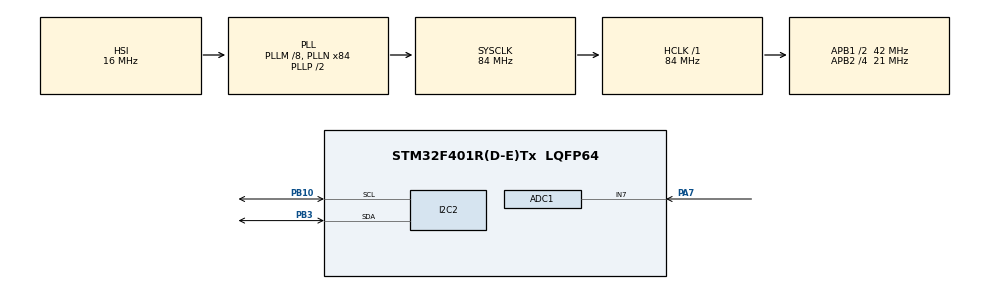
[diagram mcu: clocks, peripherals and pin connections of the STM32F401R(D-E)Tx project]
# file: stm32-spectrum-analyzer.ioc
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Mcu.Family=STM32F4
Dma.ADC1.0.Instance=DMA2_Stream0
RCC.CortexFreq_Value=84000000
PB10.Mode=I2C
ADC1.ContinuousConvMode=ENABLE
PH1\ -\ OSC_OUT.Mode=HSE-External-Oscillator
RCC.APB1CLKDivider=RCC_HCLK_DIV2
RCC.SYSCLKSource=RCC_SYSCLKSOURCE_PLLCLK
ProjectManager.StackSize=0x400
Dma.ADC1.0.PeriphDataAlignment=DMA_PDATAALIGN_HALFWORD
PH0\ -\ OSC_IN.Mode=HSE-External-Oscillator
PH0\ -\ OSC_IN.Signal=RCC_OSC_IN
ProjectManager.TargetToolchain=STM32CubeIDE
Dma.ADC1.0.Mode=DMA_CIRCULAR
SH.ADCx_IN7.0=ADC1_IN7,IN7
RCC.HCLKFreq_Value=84000000
Dma.ADC1.0.Priority=DMA_PRIORITY_LOW
RCC.APB2TimFreq_Value=42000000
ADC1.Channel-1\#ChannelRegularConversion=ADC_CHANNEL_7
Dma.ADC1.0.Direction=DMA_PERIPH_TO_MEMORY
NVIC.DMA2_Stream0_IRQn=true\:0\:0\:false\:false\:true\:false\:true
RCC.LSE_VALUE=32768
Dma.ADC1.0.MemDataAlignment=DMA_MDATAALIGN_HALFWORD
RCC.AHBFreq_Value=84000000
PB10.Signal=I2C2_SCL
RCC.HSE_VALUE=25000000
PH1\ -\ OSC_OUT.Signal=RCC_OSC_OUT
PB3.Mode=I2C
board=custom
RCC.VCOOutputFreq_Value=168000000
RCC.APB2Freq_Value=21000000
Dma.ADC1.0.PeriphInc=DMA_PINC_DISABLE
ADC1.DMAContinuousRequests=ENABLE
Mcu.Name=STM32F401R(D-E)Tx
RCC.48MHZClocksFreq_Value=42000000
PB3.Signal=I2C2_SDA
ADC1.SamplingTime-1\#ChannelRegularConversion=ADC_SAMPLETIME_3CYCLES
RCC.SYSCLKFreq_VALUE=84000000
Mcu.Package=LQFP64
ADC1.master=1
ADC1.Rank-1\#ChannelRegularConversion=1
Dma.ADC1.0.MemInc=DMA_MINC_ENABLE
ProjectManager.HeapSize=0x200
RCC.HSI_VALUE=16000000
NVIC.PriorityGroup=NVIC_PRIORITYGROUP_4
ADC1.NbrOfConversionFlag=1
RCC.APB2CLKDivider=RCC_HCLK_DIV4
RCC.PLLM=8
RCC.PLLN=84
RCC.APB1TimFreq_Value=84000000
Dma.ADC1.0.FIFOMode=DMA_FIFOMODE_DISABLE
RCC.APB1Freq_Value=42000000
Dma.Request0=ADC1
I2C2.I2C_Mode=I2C_Fast
PA7.Signal=ADCx_IN7

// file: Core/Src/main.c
/* USER CODE BEGIN Header */
/**
  ******************************************************************************
  * @file           : main.c
  * @brief          : Main program body
  ******************************************************************************
  * @attention
  *
  * <h2><center>&copy; Copyright (c) 2021 STMicroelectronics.
  * All rights reserved.</center></h2>
  *
  * This software component is licensed by ST under BSD 3-Clause license,
  * the "License"; You may not use this file except in compliance with the
  * License. You may obtain a copy of the License at:
  *                        opensource.org/licenses/BSD-3-Clause
  *
  ******************************************************************************
  */
/* USER CODE END Header */
#include "main.h"

/* USER CODE BEGIN Includes */
#include "arm_math.h"
#include "fonts.h"
#include "ssd1306.h"
/* USER CODE END Includes */

/* USER CODE BEGIN PD */
// #define ARM_MATH_CM4
#define ADC_BUF_LEN 4096
#define FFT_SIZE 256
/* USER CODE END PD */

ADC_HandleTypeDef hadc1;
DMA_HandleTypeDef hdma_adc1;

I2C_HandleTypeDef hi2c2;

/* USER CODE BEGIN PV */
uint16_t adc_buf[ADC_BUF_LEN];

//FFT buffers
float fft_in_buf[FFT_SIZE];
float fft_out_buf[FFT_SIZE];
float32_t fft_mag_buf[FFT_SIZE>>1];

arm_rfft_fast_instance_f32 fft_handler;

float real_fsample = 46785;
uint8_t callback_state = 0;

/* USER CODE END PV */

void SystemClock_Config(void);
static void MX_GPIO_Init(void);
static void MX_DMA_Init(void);
static void MX_ADC1_Init(void);
static void MX_I2C2_Init(void);
/* USER CODE BEGIN PFP */
void displayFFT(uint8_t *arr);
void FFT(void);
/* USER CODE END PFP */

int main(void)
{

  /* MCU Configuration--------------------------------------------------------*/

  /* Reset of all peripherals, Initializes the Flash interface and the Systick. */
  HAL_Init();

  /* Configure the system clock */
  SystemClock_Config();

  /* Initialize all configured peripherals */
  MX_GPIO_Init();
  MX_DMA_Init();
  MX_ADC1_Init();
  MX_I2C2_Init();
  /* USER CODE BEGIN 2 */
  if (ssd1306_Init(&hi2c2) != 0) {
    Error_Handler();
  }
  HAL_Delay(1000);

  ssd1306_Fill(Black);
  ssd1306_UpdateScreen(&hi2c2);

  HAL_ADC_Start_DMA(&hadc1, (uint32_t*)fft_in_buf, ADC_BUF_LEN);

  /* USER CODE END 2 */

  /* Infinite loop */
  /* USER CODE BEGIN WHILE */

  arm_rfft_fast_init_f32(&fft_handler, 256);

  while (1)
  {

    /* USER CODE END WHILE */

    /* USER CODE BEGIN 3 */
	  FFT();

  }
  /* USER CODE END 3 */
}

void SystemClock_Config(void)
{
  RCC_OscInitTypeDef RCC_OscInitStruct = {0};
  RCC_ClkInitTypeDef RCC_ClkInitStruct = {0};

  /** Configure the main internal regulator output voltage
  */
  __HAL_RCC_PWR_CLK_ENABLE();
  __HAL_PWR_VOLTAGESCALING_CONFIG(PWR_REGULATOR_VOLTAGE_SCALE2);
  /** Initializes the RCC Oscillators according to the specified parameters
  * in the RCC_OscInitTypeDef structure.
  */
  RCC_OscInitStruct.OscillatorType = RCC_OSCILLATORTYPE_HSI;
  RCC_OscInitStruct.HSIState = RCC_HSI_ON;
  RCC_OscInitStruct.HSICalibrationValue = RCC_HSICALIBRATION_DEFAULT;
  RCC_OscInitStruct.PLL.PLLState = RCC_PLL_ON;
  RCC_OscInitStruct.PLL.PLLSource = RCC_PLLSOURCE_HSI;
  RCC_OscInitStruct.PLL.PLLM = 8;
  RCC_OscInitStruct.PLL.PLLN = 84;
  RCC_OscInitStruct.PLL.PLLP = RCC_PLLP_DIV2;
  RCC_OscInitStruct.PLL.PLLQ = 4;
  if (HAL_RCC_OscConfig(&RCC_OscInitStruct) != HAL_OK)
  {
    Error_Handler();
  }
  /** Initializes the CPU, AHB and APB buses clocks
  */
  RCC_ClkInitStruct.ClockType = RCC_CLOCKTYPE_HCLK|RCC_CLOCKTYPE_SYSCLK
                              |RCC_CLOCKTYPE_PCLK1|RCC_CLOCKTYPE_PCLK2;
  RCC_ClkInitStruct.SYSCLKSource = RCC_SYSCLKSOURCE_PLLCLK;
  RCC_ClkInitStruct.AHBCLKDivider = RCC_SYSCLK_DIV1;
  RCC_ClkInitStruct.APB1CLKDivider = RCC_HCLK_DIV2;
  RCC_ClkInitStruct.APB2CLKDivider = RCC_HCLK_DIV4;

  if (HAL_RCC_ClockConfig(&RCC_ClkInitStruct, FLASH_LATENCY_2) != HAL_OK)
  {
    Error_Handler();
  }
}

static void MX_ADC1_Init(void)
{

  ADC_ChannelConfTypeDef sConfig = {0};

  /** Configure the global features of the ADC (Clock, Resolution, Data Alignment and number of conversion)
  */
  hadc1.Instance = ADC1;
  hadc1.Init.ClockPrescaler = ADC_CLOCK_SYNC_PCLK_DIV2;
  hadc1.Init.Resolution = ADC_RESOLUTION_12B;
  hadc1.Init.ScanConvMode = DISABLE;
  hadc1.Init.ContinuousConvMode = ENABLE;
  hadc1.Init.DiscontinuousConvMode = DISABLE;
  hadc1.Init.ExternalTrigConvEdge = ADC_EXTERNALTRIGCONVEDGE_NONE;
  hadc1.Init.ExternalTrigConv = ADC_SOFTWARE_START;
  hadc1.Init.DataAlign = ADC_DATAALIGN_RIGHT;
  hadc1.Init.NbrOfConversion = 1;
  hadc1.Init.DMAContinuousRequests = ENABLE;
  hadc1.Init.EOCSelection = ADC_EOC_SINGLE_CONV;
  if (HAL_ADC_Init(&hadc1) != HAL_OK)
  {
    Error_Handler();
  }
  /** Configure for the selected ADC regular channel its corresponding rank in the sequencer and its sample time.
  */
  sConfig.Channel = ADC_CHANNEL_7;
  sConfig.Rank = 1;
  sConfig.SamplingTime = ADC_SAMPLETIME_3CYCLES;
  if (HAL_ADC_ConfigChannel(&hadc1, &sConfig) != HAL_OK)
  {
    Error_Handler();
  }

}

static void MX_I2C2_Init(void)
{

  hi2c2.Instance = I2C2;
  hi2c2.Init.ClockSpeed = 400000;
  hi2c2.Init.DutyCycle = I2C_DUTYCYCLE_2;
  hi2c2.Init.OwnAddress1 = 0;
  hi2c2.Init.AddressingMode = I2C_ADDRESSINGMODE_7BIT;
  hi2c2.Init.DualAddressMode = I2C_DUALADDRESS_DISABLE;
  hi2c2.Init.OwnAddress2 = 0;
  hi2c2.Init.GeneralCallMode = I2C_GENERALCALL_DISABLE;
  hi2c2.Init.NoStretchMode = I2C_NOSTRETCH_DISABLE;
  if (HAL_I2C_Init(&hi2c2) != HAL_OK)
  {
    Error_Handler();
  }

}

static void MX_DMA_Init(void)
{

  /* DMA controller clock enable */
  __HAL_RCC_DMA2_CLK_ENABLE();

  /* DMA interrupt init */
  /* DMA2_Stream0_IRQn interrupt configuration */
  HAL_NVIC_SetPriority(DMA2_Stream0_IRQn, 0, 0);
  HAL_NVIC_EnableIRQ(DMA2_Stream0_IRQn);

}

static void MX_GPIO_Init(void)
{

  /* GPIO Ports Clock Enable */
  __HAL_RCC_GPIOH_CLK_ENABLE();
  __HAL_RCC_GPIOA_CLK_ENABLE();
  __HAL_RCC_GPIOB_CLK_ENABLE();

}

/* USER CODE BEGIN 4 */

float complexABS(float real, float complex){
	return sqrtf(real*real+complex*complex);
}

void FFT(void) {
	//Do FFT
	arm_rfft_fast_f32(&fft_handler, fft_in_buf, fft_out_buf,0);
	/* Calculate magnitude (buffer size is half because real + imag parts are merged) */
	arm_cmplx_mag_f32(fft_out_buf, fft_mag_buf, FFT_SIZE >> 1);

	displayFFT((uint8_t*)fft_mag_buf);

}

void displayFFT(uint8_t *arr){
	  ssd1306_Fill(Black);
	  for (uint8_t i=0; i<128; i++) {
	      for (uint8_t j=64; j>64-arr[i]; j--) {
	          ssd1306_DrawPixel(i, j, White);
	      }
	  }
	  ssd1306_UpdateScreen(&hi2c2);
	  HAL_Delay(50);
}

void HAL_ADC_ConvHalfCpltCallback(ADC_HandleTypeDef* hadc) {
	callback_state = 1;
}

// Called when buffer is completely filled
void HAL_ADC_ConvCpltCallback(ADC_HandleTypeDef* hadc) {
	callback_state = 2;
}

/* USER CODE END 4 */

void Error_Handler(void)
{
  __disable_irq();
  while (1)
  {
  }
}

/************************ (C) COPYRIGHT STMicroelectronics *****END OF FILE****/
